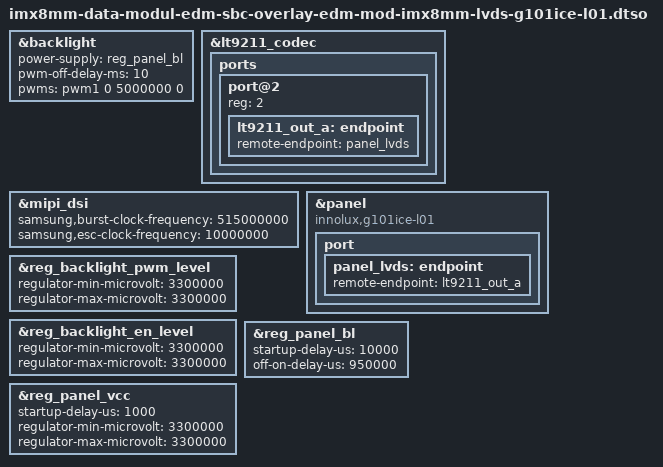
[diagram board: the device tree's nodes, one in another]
// SPDX-License-Identifier: (GPL-2.0+ OR MIT)
/*
 * Copyright 2023-2026 Marek Vasut
 */

#include "imx8mm-data-modul-edm-sbc-overlay-edm-mod-imx8mm-lvds.dtsi"

&backlight {
	power-supply = <&reg_panel_bl>;
	/* 6.3 POWER ON/OFF SEQUENCE, T9 >= 10 ms */
	pwm-off-delay-ms = <10>;
	/* 3.2 BACKLIGHT UNIT fPWM=200 Hz (Typ.), value below in ns */
	pwms = <&pwm1 0 5000000 0>;
	status = "okay";
};

&lt9211_codec {
	ports {
		port@2 {
			reg = <2>;

			lt9211_out_a: endpoint {
				remote-endpoint = <&panel_lvds>;
			};
		};
	};
};

&mipi_dsi {
	samsung,burst-clock-frequency = <515000000>;
	samsung,esc-clock-frequency = <10000000>;
};

&panel {
	compatible = "innolux,g101ice-l01";
	status = "okay";

	port {
		panel_lvds: endpoint {
			remote-endpoint = <&lt9211_out_a>;
		};
	};
};

&reg_backlight_pwm_level {
	/* Always only output 3.3V on this G101ICE-L01 panel unit. */
	regulator-min-microvolt = <3300000>;
	regulator-max-microvolt = <3300000>;
};

&reg_backlight_en_level {
	/* Always only output 3.3V on this G101ICE-L01 panel unit. */
	regulator-min-microvolt = <3300000>;
	regulator-max-microvolt = <3300000>;
};

&reg_panel_bl {
	startup-delay-us = <10000>; /* T8 */
	off-on-delay-us = <950000>; /* T9 + T6 + T3 + T7 + T4 + T1 + T2 + T5 */
	status = "okay";
};

&reg_panel_vcc {
	/* 6.3 POWER ON/OFF SEQUENCE */
	startup-delay-us = <1000>; /* 0.5ms <= T1 + T2 <= 60 ms */

	/* Always only output 3.3V on this G101ICE-L01 panel unit. */
	regulator-min-microvolt = <3300000>;
	regulator-max-microvolt = <3300000>;
};
